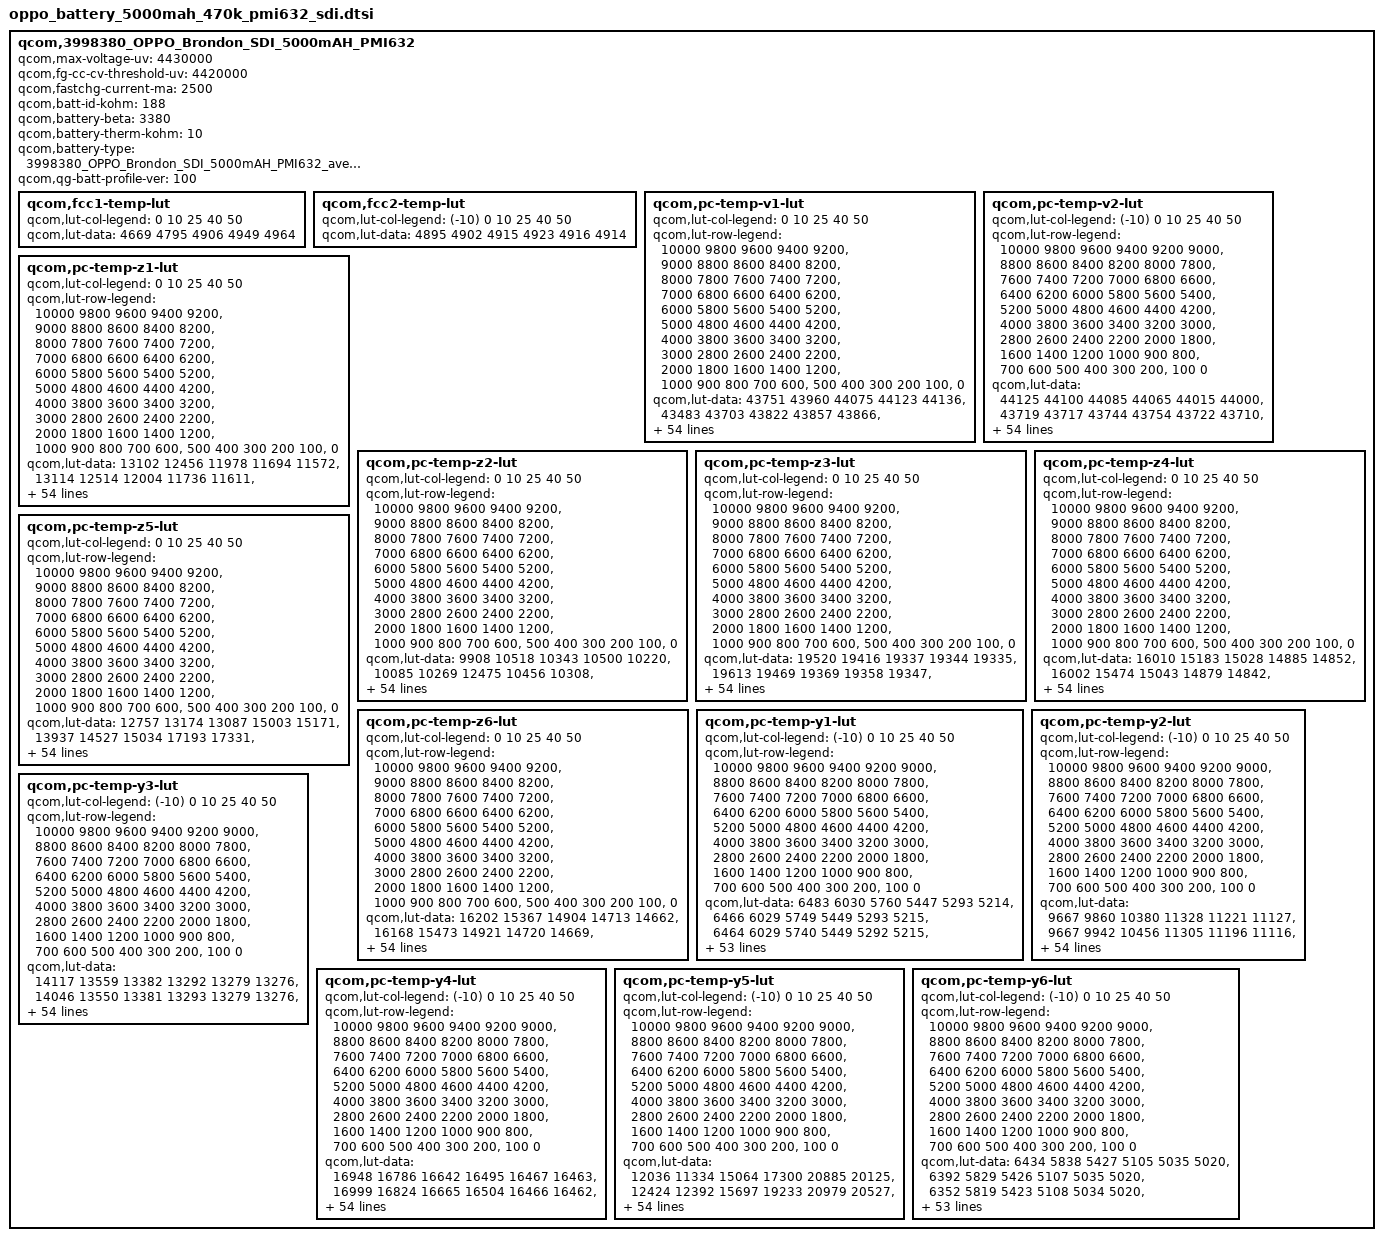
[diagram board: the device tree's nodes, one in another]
qcom,3998380_OPPO_Brondon_SDI_5000mAH_PMI632 {
    /* 3998380_OPPO_Brondon_SDI_5000mAH_PMI632_averaged_MasterSlave_Jun3th2019 */
    qcom,max-voltage-uv = <4430000>;
    qcom,fg-cc-cv-threshold-uv = <4420000>;
    qcom,fastchg-current-ma = <2500>;
    qcom,batt-id-kohm = <188>;
    qcom,battery-beta = <3380>;
    qcom,battery-therm-kohm = <10>;
    qcom,battery-type = "3998380_OPPO_Brondon_SDI_5000mAH_PMI632_averaged_MasterSlave_Jun3th2019";
    qcom,qg-batt-profile-ver = <100>;

	qcom,fcc1-temp-lut {
		qcom,lut-col-legend = <0 10 25 40 50>;
		qcom,lut-data = <4669 4795 4906 4949 4964>;
	};

	qcom,fcc2-temp-lut {
		qcom,lut-col-legend = <(-10) 0 10 25 40 50>;
		qcom,lut-data = <4895 4902 4915 4923 4916 4914>;
	};

	qcom,pc-temp-v1-lut {
		qcom,lut-col-legend = <0 10 25 40 50>;
		qcom,lut-row-legend = <10000 9800 9600 9400 9200>,
			<9000 8800 8600 8400 8200>,
			<8000 7800 7600 7400 7200>,
			<7000 6800 6600 6400 6200>,
			<6000 5800 5600 5400 5200>,
			<5000 4800 4600 4400 4200>,
			<4000 3800 3600 3400 3200>,
			<3000 2800 2600 2400 2200>,
			<2000 1800 1600 1400 1200>,
			<1000 900 800 700 600>,
			<500 400 300 200 100>,
			<0>;
		qcom,lut-data = <43751 43960 44075 44123 44136>,
			<43483 43703 43822 43857 43866>,
			<43224 43456 43576 43603 43610>,
			<42977 43212 43339 43366 43373>,
			<42736 42967 43102 43138 43148>,
			<42498 42723 42857 42904 42918>,
			<42263 42482 42609 42665 42681>,
			<42032 42245 42366 42426 42441>,
			<41807 42012 42128 42189 42204>,
			<41586 41784 41894 41954 41967>,
			<41369 41559 41665 41722 41735>,
			<41158 41340 41442 41491 41508>,
			<40950 41128 41225 41265 41284>,
			<40745 40923 41018 41048 41065>,
			<40537 40720 40815 40836 40850>,
			<40338 40517 40615 40632 40644>,
			<40152 40322 40415 40433 40445>,
			<39976 40143 40227 40244 40254>,
			<39814 39973 40055 40069 40076>,
			<39667 39811 39888 39905 39907>,
			<39532 39662 39711 39728 39729>,
			<39398 39510 39524 39528 39527>,
			<39271 39325 39333 39326 39324>,
			<39146 39101 39113 39128 39132>,
			<39023 38905 38897 38933 38947>,
			<38902 38759 38761 38784 38795>,
			<38785 38638 38671 38677 38678>,
			<38670 38548 38595 38585 38577>,
			<38562 38480 38517 38493 38478>,
			<38476 38423 38445 38404 38384>,
			<38407 38371 38380 38325 38301>,
			<38349 38323 38318 38252 38229>,
			<38300 38280 38262 38187 38164>,
			<38258 38242 38209 38131 38102>,
			<38220 38206 38160 38083 38045>,
			<38185 38170 38112 38032 37986>,
			<38150 38137 38068 37979 37926>,
			<38107 38095 38020 37919 37861>,
			<38051 38031 37952 37843 37778>,
			<37982 37946 37864 37747 37675>,
			<37890 37848 37763 37644 37566>,
			<37767 37733 37646 37540 37460>,
			<37641 37599 37512 37419 37341>,
			<37506 37435 37351 37260 37178>,
			<37351 37283 37204 37118 37040>,
			<37235 37169 37096 37017 36955>,
			<37195 37137 37060 36981 36926>,
			<37160 37111 37033 36957 36899>,
			<37125 37084 37013 36934 36876>,
			<37063 37042 36965 36885 36814>,
			<36867 36856 36751 36642 36545>,
			<36433 36422 36320 36211 36116>,
			<35860 35851 35755 35647 35554>,
			<35084 35070 34985 34880 34786>,
			<33833 33825 33776 33687 33589>,
			<30000 30000 30000 30000 30000>;
	};

	qcom,pc-temp-v2-lut {
		qcom,lut-col-legend = <(-10) 0 10 25 40 50>;
		qcom,lut-row-legend = <10000 9800 9600 9400 9200 9000>,
			<8800 8600 8400 8200 8000 7800>,
			<7600 7400 7200 7000 6800 6600>,
			<6400 6200 6000 5800 5600 5400>,
			<5200 5000 4800 4600 4400 4200>,
			<4000 3800 3600 3400 3200 3000>,
			<2800 2600 2400 2200 2000 1800>,
			<1600 1400 1200 1000 900 800>,
			<700 600 500 400 300 200>,
			<100 0>;
		qcom,lut-data = <44125 44100 44085 44065 44015 44000>,
			<43719 43717 43744 43754 43722 43710>,
			<43347 43369 43428 43464 43446 43438>,
			<43014 43062 43140 43199 43189 43182>,
			<42715 42792 42879 42959 42951 42946>,
			<42438 42535 42626 42724 42717 42713>,
			<42170 42280 42369 42480 42477 42474>,
			<41916 42032 42115 42237 42238 42235>,
			<41670 41783 41870 41998 42001 41998>,
			<41428 41527 41634 41763 41764 41763>,
			<41206 41286 41405 41532 41532 41532>,
			<41027 41082 41180 41305 41305 41305>,
			<40873 40899 40960 41083 41082 41082>,
			<40666 40700 40751 40869 40867 40866>,
			<40323 40478 40554 40661 40660 40655>,
			<39964 40246 40357 40460 40460 40451>,
			<39719 40008 40144 40262 40265 40258>,
			<39527 39761 39922 40068 40077 40073>,
			<39344 39526 39703 39881 39894 39893>,
			<39160 39306 39487 39704 39725 39728>,
			<38984 39101 39278 39524 39552 39557>,
			<38816 38915 39078 39308 39340 39348>,
			<38653 38747 38885 39065 39094 39102>,
			<38514 38592 38714 38860 38885 38892>,
			<38404 38443 38569 38703 38728 38734>,
			<38310 38309 38438 38569 38594 38599>,
			<38227 38213 38314 38449 38475 38479>,
			<38152 38140 38195 38343 38369 38373>,
			<38083 38078 38096 38247 38275 38277>,
			<38018 38019 38021 38159 38188 38187>,
			<37957 37967 37960 38080 38110 38105>,
			<37896 37918 37908 38005 38039 38032>,
			<37837 37871 37865 37934 37975 37970>,
			<37776 37824 37824 37868 37909 37905>,
			<37716 37774 37782 37807 37837 37827>,
			<37654 37720 37739 37750 37759 37739>,
			<37589 37663 37687 37687 37673 37642>,
			<37520 37602 37623 37622 37572 37529>,
			<37448 37535 37549 37551 37473 37421>,
			<37374 37458 37464 37472 37391 37335>,
			<37298 37371 37366 37386 37314 37257>,
			<37223 37275 37261 37288 37223 37167>,
			<37149 37164 37144 37171 37107 37053>,
			<37073 37049 37030 37047 36989 36935>,
			<36991 36931 36922 36919 36874 36815>,
			<36898 36825 36799 36837 36818 36769>,
			<36844 36778 36731 36814 36800 36752>,
			<36777 36734 36671 36789 36782 36735>,
			<36692 36680 36610 36748 36751 36702>,
			<36568 36599 36511 36664 36659 36600>,
			<36365 36422 36322 36413 36378 36288>,
			<36013 36057 35957 35931 35887 35792>,
			<35482 35481 35375 35285 35252 35150>,
			<34660 34644 34561 34388 34380 34268>,
			<33336 33260 33221 33044 33098 32929>,
			<29596 28808 28689 28773 29047 29152>;
	};

	qcom,pc-temp-z1-lut {
		qcom,lut-col-legend = <0 10 25 40 50>;
		qcom,lut-row-legend = <10000 9800 9600 9400 9200>,
			<9000 8800 8600 8400 8200>,
			<8000 7800 7600 7400 7200>,
			<7000 6800 6600 6400 6200>,
			<6000 5800 5600 5400 5200>,
			<5000 4800 4600 4400 4200>,
			<4000 3800 3600 3400 3200>,
			<3000 2800 2600 2400 2200>,
			<2000 1800 1600 1400 1200>,
			<1000 900 800 700 600>,
			<500 400 300 200 100>,
			<0>;
		qcom,lut-data = <13102 12456 11978 11694 11572>,
			<13114 12514 12004 11736 11611>,
			<13120 12508 12015 11757 11633>,
			<13122 12498 12017 11750 11632>,
			<13122 12495 12019 11737 11629>,
			<13117 12492 12012 11729 11625>,
			<13101 12488 11994 11725 11620>,
			<13081 12476 11980 11722 11616>,
			<13059 12459 11968 11716 11613>,
			<13035 12444 11960 11709 11611>,
			<13016 12426 11958 11704 11609>,
			<13004 12412 11957 11700 11606>,
			<12993 12400 11956 11697 11603>,
			<12976 12391 11954 11694 11600>,
			<12946 12386 11952 11691 11598>,
			<12921 12383 11949 11689 11596>,
			<12911 12382 11944 11688 11594>,
			<12904 12382 11942 11687 11593>,
			<12902 12384 11943 11687 11593>,
			<12905 12387 11946 11687 11594>,
			<12907 12394 11949 11687 11594>,
			<12906 12403 11954 11688 11594>,
			<12905 12410 11958 11688 11593>,
			<12908 12416 11957 11689 11594>,
			<12917 12420 11956 11690 11596>,
			<12929 12421 11956 11692 11598>,
			<12936 12421 11962 11696 11601>,
			<12936 12424 11966 11701 11603>,
			<12934 12433 11966 11704 11606>,
			<12935 12441 11966 11706 11609>,
			<12942 12441 11967 11708 11612>,
			<12950 12442 11971 11712 11615>,
			<12960 12443 11977 11717 11619>,
			<12980 12445 11983 11721 11623>,
			<12991 12447 11988 11725 11627>,
			<12987 12451 11993 11729 11632>,
			<12982 12461 11996 11733 11635>,
			<12985 12472 12000 11737 11639>,
			<12996 12482 12007 11743 11644>,
			<13009 12492 12014 11750 11649>,
			<13021 12503 12021 11757 11654>,
			<13032 12514 12026 11763 11658>,
			<13045 12527 12031 11767 11662>,
			<13061 12543 12041 11767 11667>,
			<13103 12537 12046 11776 11671>,
			<13054 12539 12047 11781 11673>,
			<13069 12555 12063 11784 11672>,
			<13071 12565 12048 11783 11673>,
			<13091 12548 12056 11784 11678>,
			<13110 12544 12075 11788 11682>,
			<13080 12548 12076 11799 11691>,
			<13088 12568 12077 11807 11697>,
			<13092 12608 12087 11818 11708>,
			<13135 12642 12114 11835 11721>,
			<13135 12642 12114 11835 11721>,
			<13135 12642 12114 11835 11721>;
	};

	qcom,pc-temp-z2-lut {
		qcom,lut-col-legend = <0 10 25 40 50>;
		qcom,lut-row-legend = <10000 9800 9600 9400 9200>,
			<9000 8800 8600 8400 8200>,
			<8000 7800 7600 7400 7200>,
			<7000 6800 6600 6400 6200>,
			<6000 5800 5600 5400 5200>,
			<5000 4800 4600 4400 4200>,
			<4000 3800 3600 3400 3200>,
			<3000 2800 2600 2400 2200>,
			<2000 1800 1600 1400 1200>,
			<1000 900 800 700 600>,
			<500 400 300 200 100>,
			<0>;
		qcom,lut-data = <9908 10518 10343 10500 10220>,
			<10085 10269 12475 10456 10308>,
			<10186 10382 12866 10438 10355>,
			<10236 10446 12356 10450 10352>,
			<10266 10437 11736 10470 10340>,
			<10275 10407 11201 10473 10337>,
			<10276 10381 10701 10464 10340>,
			<10275 10365 10536 10450 10339>,
			<10271 10350 10491 10403 10309>,
			<10261 10337 10464 10329 10246>,
			<10251 10325 10592 10298 10213>,
			<10243 10318 10927 10290 10201>,
			<10235 10316 11109 10291 10194>,
			<10224 10314 11402 10309 10203>,
			<10202 10316 11763 10336 10230>,
			<10185 10332 11896 10344 10247>,
			<10184 10354 11977 10323 10254>,
			<10184 10371 12000 10305 10259>,
			<10184 10388 11417 10309 10273>,
			<10191 10408 10634 10315 10295>,
			<10203 10432 10513 10329 10314>,
			<10210 10458 10557 10378 10337>,
			<10216 10482 10588 10420 10359>,
			<10221 10508 10592 10416 10373>,
			<10235 10522 10594 10396 10386>,
			<10260 10522 10595 10380 10395>,
			<10280 10522 10589 10384 10468>,
			<10291 10523 10583 10399 10553>,
			<10301 10533 10578 10440 10560>,
			<10312 10543 10574 10523 10536>,
			<10326 10547 10573 10557 10490>,
			<10339 10552 10584 10521 10370>,
			<10347 10554 10596 10464 10251>,
			<10354 10554 10605 10409 10237>,
			<10361 10554 10612 10349 10238>,
			<10371 10557 10617 10325 10241>,
			<10385 10573 10618 10341 10266>,
			<10403 10593 10619 10373 10310>,
			<10434 10613 10628 10428 10355>,
			<10463 10633 10651 10537 10412>,
			<10477 10640 10670 10591 10438>,
			<10488 10636 10686 10530 10420>,
			<10339 10635 10695 10477 10403>,
			<9937 10651 10686 10476 10408>,
			<10052 10786 10703 10500 10410>,
			<10076 10822 10667 10549 10400>,
			<10142 10805 10630 10489 10415>,
			<10181 10785 10653 10522 10427>,
			<10271 10793 10654 10524 10457>,
			<10340 11036 10689 10643 10530>,
			<10128 11444 10710 10492 10397>,
			<9900 10452 10664 10407 10264>,
			<9755 10492 10567 10379 10224>,
			<9628 10151 10476 10309 10175>,
			<9628 10151 10476 10309 10175>,
			<9628 10151 10476 10309 10175>;
	};

	qcom,pc-temp-z3-lut {
		qcom,lut-col-legend = <0 10 25 40 50>;
		qcom,lut-row-legend = <10000 9800 9600 9400 9200>,
			<9000 8800 8600 8400 8200>,
			<8000 7800 7600 7400 7200>,
			<7000 6800 6600 6400 6200>,
			<6000 5800 5600 5400 5200>,
			<5000 4800 4600 4400 4200>,
			<4000 3800 3600 3400 3200>,
			<3000 2800 2600 2400 2200>,
			<2000 1800 1600 1400 1200>,
			<1000 900 800 700 600>,
			<500 400 300 200 100>,
			<0>;
		qcom,lut-data = <19520 19416 19337 19344 19335>,
			<19613 19469 19369 19358 19347>,
			<19654 19505 19385 19368 19356>,
			<19661 19531 19404 19374 19361>,
			<19664 19541 19421 19378 19364>,
			<19664 19547 19427 19381 19368>,
			<19655 19549 19431 19384 19373>,
			<19644 19545 19432 19385 19376>,
			<19635 19540 19431 19384 19376>,
			<19625 19534 19430 19382 19376>,
			<19620 19528 19430 19381 19374>,
			<19619 19521 19433 19378 19370>,
			<19618 19515 19434 19376 19366>,
			<19616 19509 19435 19374 19363>,
			<19614 19503 19436 19372 19361>,
			<19611 19496 19434 19369 19360>,
			<19604 19490 19430 19366 19357>,
			<19594 19483 19425 19363 19355>,
			<19582 19474 19410 19359 19352>,
			<19565 19470 19395 19356 19348>,
			<19548 19467 19393 19354 19347>,
			<19542 19465 19397 19357 19349>,
			<19546 19468 19400 19360 19351>,
			<19551 19480 19399 19358 19348>,
			<19559 19488 19398 19352 19340>,
			<19575 19488 19398 19350 19336>,
			<19586 19486 19396 19351 19349>,
			<19591 19485 19395 19354 19366>,
			<19594 19483 19396 19361 19373>,
			<19594 19480 19399 19374 19379>,
			<19587 19478 19401 19379 19381>,
			<19578 19475 19402 19379 19376>,
			<19570 19472 19403 19379 19368>,
			<19562 19469 19403 19376 19362>,
			<19553 19466 19402 19370 19358>,
			<19543 19463 19401 19364 19353>,
			<19532 19459 19397 19358 19347>,
			<19523 19456 19392 19354 19342>,
			<19513 19454 19391 19354 19342>,
			<19506 19452 19389 19355 19342>,
			<19504 19449 19388 19355 19343>,
			<19503 19443 19384 19350 19342>,
			<19438 19440 19382 19347 19342>,
			<19267 19439 19380 19348 19346>,
			<19263 19419 19373 19345 19345>,
			<19263 19410 19366 19340 19338>,
			<19263 19379 19362 19339 19329>,
			<19262 19330 19364 19333 19324>,
			<19262 19299 19351 19330 19320>,
			<19261 19263 19349 19318 19313>,
			<19262 19260 19346 19337 19335>,
			<19265 19266 19346 19345 19344>,
			<19266 19264 19349 19345 19340>,
			<19269 19269 19355 19346 19341>,
			<19269 19269 19355 19346 19341>,
			<19269 19269 19355 19346 19341>;
	};

	qcom,pc-temp-z4-lut {
		qcom,lut-col-legend = <0 10 25 40 50>;
		qcom,lut-row-legend = <10000 9800 9600 9400 9200>,
			<9000 8800 8600 8400 8200>,
			<8000 7800 7600 7400 7200>,
			<7000 6800 6600 6400 6200>,
			<6000 5800 5600 5400 5200>,
			<5000 4800 4600 4400 4200>,
			<4000 3800 3600 3400 3200>,
			<3000 2800 2600 2400 2200>,
			<2000 1800 1600 1400 1200>,
			<1000 900 800 700 600>,
			<500 400 300 200 100>,
			<0>;
		qcom,lut-data = <16010 15183 15028 14885 14852>,
			<16002 15474 15043 14879 14842>,
			<15978 15367 15036 14868 14830>,
			<15824 15231 14964 14845 14814>,
			<15594 15126 14882 14813 14794>,
			<15437 15025 14840 14787 14776>,
			<15321 14949 14809 14766 14759>,
			<15224 14891 14782 14748 14743>,
			<15146 14845 14759 14732 14728>,
			<15080 14810 14737 14718 14714>,
			<15023 14782 14713 14708 14706>,
			<14973 14758 14686 14700 14703>,
			<14929 14738 14669 14695 14700>,
			<14896 14720 14653 14689 14696>,
			<14869 14711 14639 14684 14691>,
			<14848 14705 14637 14680 14687>,
			<14830 14700 14636 14678 14683>,
			<14815 14695 14636 14675 14679>,
			<14806 14691 14644 14670 14674>,
			<14803 14686 14659 14663 14667>,
			<14800 14679 14670 14661 14665>,
			<14794 14674 14680 14677 14681>,
			<14781 14682 14693 14701 14707>,
			<14765 14720 14734 14732 14734>,
			<14750 14753 14784 14770 14767>,
			<14729 14766 14794 14783 14780>,
			<14719 14775 14782 14773 14759>,
			<14722 14776 14767 14755 14728>,
			<14726 14765 14754 14736 14710>,
			<14726 14750 14741 14714 14696>,
			<14725 14738 14729 14700 14687>,
			<14723 14727 14718 14692 14683>,
			<14720 14717 14708 14686 14679>,
			<14715 14708 14700 14680 14674>,
			<14710 14699 14694 14675 14668>,
			<14706 14690 14689 14672 14665>,
			<14703 14681 14684 14671 14665>,
			<14699 14677 14681 14670 14665>,
			<14696 14676 14681 14672 14668>,
			<14692 14676 14681 14677 14678>,
			<14689 14675 14681 14680 14684>,
			<14685 14673 14678 14676 14675>,
			<14751 14671 14673 14671 14667>,
			<14928 14667 14669 14668 14667>,
			<14876 14656 14656 14657 14659>,
			<14871 14653 14651 14649 14648>,
			<14866 14679 14648 14645 14646>,
			<14862 14728 14639 14638 14640>,
			<14857 14757 14640 14627 14626>,
			<14854 14788 14635 14629 14621>,
			<14857 14793 14649 14632 14636>,
			<14879 14808 14662 14640 14645>,
			<14895 14817 14663 14644 14652>,
			<14913 14827 14661 14648 14655>,
			<14913 14827 14661 14648 14655>,
			<14913 14827 14661 14648 14655>;
	};

	qcom,pc-temp-z5-lut {
		qcom,lut-col-legend = <0 10 25 40 50>;
		qcom,lut-row-legend = <10000 9800 9600 9400 9200>,
			<9000 8800 8600 8400 8200>,
			<8000 7800 7600 7400 7200>,
			<7000 6800 6600 6400 6200>,
			<6000 5800 5600 5400 5200>,
			<5000 4800 4600 4400 4200>,
			<4000 3800 3600 3400 3200>,
			<3000 2800 2600 2400 2200>,
			<2000 1800 1600 1400 1200>,
			<1000 900 800 700 600>,
			<500 400 300 200 100>,
			<0>;
		qcom,lut-data = <12757 13174 13087 15003 15171>,
			<13937 14527 15034 17193 17331>,
			<14815 15610 16425 18786 18953>,
			<15417 16729 17558 19707 19880>,
			<15907 17762 18728 20390 20528>,
			<16387 18725 20120 21170 21372>,
			<16851 19602 21636 22142 22600>,
			<17268 20410 22906 22930 23924>,
			<17608 21174 23834 23390 25307>,
			<17910 21905 24915 23881 26699>,
			<18284 22609 27396 24531 27107>,
			<18904 23416 31589 25534 26823>,
			<19665 24623 35065 26592 26546>,
			<20422 25968 39311 27616 26893>,
			<21283 26946 43114 28691 28079>,
			<21933 28076 44023 29374 29234>,
			<22150 28889 44352 29758 30168>,
			<22134 28875 44355 30125 31204>,
			<21905 28587 39979 30803 32763>,
			<20838 28607 34191 31964 34820>,
			<19499 30377 34908 33505 36168>,
			<19275 33892 42533 36402 37139>,
			<20197 40978 47350 38667 37805>,
			<21632 56282 44463 35751 34826>,
			<24430 65485 38877 27393 25191>,
			<30326 62471 34639 22974 20678>,
			<36425 56294 30787 21661 21800>,
			<43098 51806 28731 20974 23752>,
			<49026 48380 28951 22096 26550>,
			<50193 45931 29655 26108 31461>,
			<48714 44776 30682 29948 33763>,
			<46543 43993 32776 33558 33700>,
			<44133 43571 35468 36329 33591>,
			<41040 43487 38980 37060 34044>,
			<38285 43557 43041 37415 35577>,
			<35337 43634 44337 37562 36380>,
			<32237 43846 44077 37450 35741>,
			<30396 44103 43665 37365 34899>,
			<29059 45123 43152 37899 34907>,
			<28257 46804 42094 39255 35450>,
			<28935 46756 40645 39871 35743>,
			<30838 41165 37578 33653 33042>,
			<25834 38607 35335 28654 30695>,
			<11634 40326 34849 30327 35680>,
			<11744 37891 34077 30263 36866>,
			<11739 35109 30462 27926 29902>,
			<11690 24214 28956 26723 23383>,
			<11638 19092 31555 25259 22517>,
			<11628 13253 24542 27291 24244>,
			<11632 11757 24820 21560 24032>,
			<11661 11733 21301 29828 34762>,
			<11700 11804 18897 26409 27413>,
			<11568 11671 18705 23871 22106>,
			<11469 11609 19375 21524 19357>,
			<11469 11609 19375 21524 19357>,
			<11469 11609 19375 21524 19357>;
	};

	qcom,pc-temp-z6-lut {
		qcom,lut-col-legend = <0 10 25 40 50>;
		qcom,lut-row-legend = <10000 9800 9600 9400 9200>,
			<9000 8800 8600 8400 8200>,
			<8000 7800 7600 7400 7200>,
			<7000 6800 6600 6400 6200>,
			<6000 5800 5600 5400 5200>,
			<5000 4800 4600 4400 4200>,
			<4000 3800 3600 3400 3200>,
			<3000 2800 2600 2400 2200>,
			<2000 1800 1600 1400 1200>,
			<1000 900 800 700 600>,
			<500 400 300 200 100>,
			<0>;
		qcom,lut-data = <16202 15367 14904 14713 14662>,
			<16168 15473 14921 14720 14669>,
			<16106 15405 14919 14722 14671>,
			<15985 15318 14888 14715 14667>,
			<15835 15249 14849 14700 14659>,
			<15721 15181 14825 14688 14653>,
			<15629 15124 14804 14678 14647>,
			<15550 15076 14786 14669 14642>,
			<15484 15036 14768 14660 14636>,
			<15427 15003 14753 14651 14629>,
			<15380 14975 14739 14645 14624>,
			<15339 14951 14728 14639 14619>,
			<15304 14929 14719 14635 14615>,
			<15272 14910 14712 14630 14611>,
			<15244 14898 14706 14626 14608>,
			<15219 14890 14702 14623 14604>,
			<15196 14884 14699 14620 14601>,
			<15175 14877 14696 14616 14597>,
			<15159 14871 14692 14612 14593>,
			<15146 14868 14689 14606 14588>,
			<15136 14865 14689 14605 14587>,
			<15133 14864 14696 14613 14594>,
			<15133 14870 14705 14625 14606>,
			<15133 14894 14724 14638 14617>,
			<15134 14914 14746 14652 14627>,
			<15137 14921 14750 14657 14632>,
			<15142 14925 14745 14653 14629>,
			<15148 14926 14739 14648 14626>,
			<15155 14921 14735 14645 14623>,
			<15157 14915 14732 14643 14621>,
			<15155 14911 14729 14640 14618>,
			<15152 14907 14726 14638 14614>,
			<15150 14903 14724 14635 14609>,
			<15147 14900 14722 14632 14605>,
			<15144 14897 14720 14627 14601>,
			<15142 14895 14719 14623 14597>,
			<15141 14893 14717 14621 14594>,
			<15141 14892 14715 14619 14592>,
			<15142 14895 14716 14620 14593>,
			<15144 14900 14719 14625 14598>,
			<15149 14903 14720 14627 14601>,
			<15156 14905 14720 14624 14598>,
			<15161 14907 14720 14621 14595>,
			<15164 14913 14721 14621 14598>,
			<15159 14910 14716 14617 14595>,
			<15155 14907 14713 14611 14587>,
			<15153 14905 14711 14610 14582>,
			<15153 14900 14708 14604 14576>,
			<15154 14899 14703 14598 14569>,
			<15156 14900 14703 14594 14564>,
			<15166 14907 14712 14607 14583>,
			<15185 14923 14721 14618 14594>,
			<15206 14935 14728 14622 14598>,
			<15234 14957 14738 14628 14603>,
			<15234 14957 14738 14628 14603>,
			<15234 14957 14738 14628 14603>;
	};

	qcom,pc-temp-y1-lut {
		qcom,lut-col-legend = <(-10) 0 10 25 40 50>;
		qcom,lut-row-legend = <10000 9800 9600 9400 9200 9000>,
			<8800 8600 8400 8200 8000 7800>,
			<7600 7400 7200 7000 6800 6600>,
			<6400 6200 6000 5800 5600 5400>,
			<5200 5000 4800 4600 4400 4200>,
			<4000 3800 3600 3400 3200 3000>,
			<2800 2600 2400 2200 2000 1800>,
			<1600 1400 1200 1000 900 800>,
			<700 600 500 400 300 200>,
			<100 0>;
		qcom,lut-data = <6483 6030 5760 5447 5293 5214>,
			<6466 6029 5749 5449 5293 5215>,
			<6464 6029 5740 5449 5292 5215>,
			<6471 6029 5733 5448 5291 5214>,
			<6480 6029 5729 5447 5288 5213>,
			<6485 6030 5726 5446 5286 5210>,
			<6494 6039 5726 5443 5282 5207>,
			<6512 6058 5727 5440 5278 5203>,
			<6517 6063 5729 5438 5274 5200>,
			<6510 6050 5730 5436 5269 5197>,
			<6503 6039 5731 5434 5265 5195>,
			<6503 6037 5733 5432 5263 5193>,
			<6508 6036 5738 5428 5260 5192>,
			<6512 6036 5739 5427 5258 5190>,
			<6525 6042 5732 5427 5255 5187>,
			<6539 6049 5726 5427 5253 5185>,
			<6539 6055 5725 5425 5251 5185>,
			<6534 6060 5724 5422 5250 5187>,
			<6528 6062 5724 5421 5249 5188>,
			<6511 6056 5727 5425 5248 5184>,
			<6491 6049 5729 5430 5248 5181>,
			<6483 6053 5729 5430 5248 5180>,
			<6475 6069 5729 5429 5249 5181>,
			<6472 6080 5729 5428 5250 5181>,
			<6480 6082 5729 5430 5250 5182>,
			<6493 6081 5728 5432 5250 5183>,
			<6498 6080 5731 5432 5251 5184>,
			<6509 6071 5743 5432 5254 5186>,
			<6516 6065 5751 5432 5257 5188>,
			<6507 6059 5744 5435 5259 5191>,
			<6489 6051 5734 5438 5262 5193>,
			<6481 6048 5731 5441 5264 5195>,
			<6479 6046 5731 5444 5267 5195>,
			<6479 6045 5731 5446 5269 5195>,
			<6483 6050 5732 5447 5273 5197>,
			<6488 6061 5733 5447 5276 5200>,
			<6489 6064 5734 5448 5277 5202>,
			<6479 6064 5740 5452 5277 5205>,
			<6468 6063 5744 5455 5277 5207>,
			<6468 6059 5750 5455 5279 5208>,
			<6474 6051 5760 5455 5282 5208>,
			<6477 6044 5761 5456 5284 5210>,
			<6468 6036 5749 5458 5285 5213>,
			<6460 6035 5741 5463 5288 5216>,
			<6442 6048 5739 5471 5295 5218>,
			<6445 6062 5745 5485 5300 5223>,
			<6454 6072 5751 5488 5302 5225>,
			<6470 6074 5756 5486 5304 5225>,
			<6480 6067 5752 5485 5304 5224>,
			<6527 6086 5756 5492 5302 5222>,
			<6464 6063 5757 5495 5304 5222>,
			<6537 6101 5759 5505 5313 5235>,
			<6569 6092 5780 5521 5321 5241>,
			<6666 6115 5788 5529 5336 5249>,
			<6666 6115 5788 5529 5336 5249>,
			<6666 6115 5788 5529 5336 5249>;
	};

	qcom,pc-temp-y2-lut {
		qcom,lut-col-legend = <(-10) 0 10 25 40 50>;
		qcom,lut-row-legend = <10000 9800 9600 9400 9200 9000>,
			<8800 8600 8400 8200 8000 7800>,
			<7600 7400 7200 7000 6800 6600>,
			<6400 6200 6000 5800 5600 5400>,
			<5200 5000 4800 4600 4400 4200>,
			<4000 3800 3600 3400 3200 3000>,
			<2800 2600 2400 2200 2000 1800>,
			<1600 1400 1200 1000 900 800>,
			<700 600 500 400 300 200>,
			<100 0>;
		qcom,lut-data = <9667 9860 10380 11328 11221 11127>,
			<9667 9942 10456 11305 11196 11116>,
			<9668 10029 10537 11282 11166 11094>,
			<9670 10113 10615 11258 11134 11067>,
			<9671 10185 10681 11234 11106 11043>,
			<9672 10235 10727 11210 11085 11029>,
			<9672 10260 10755 11185 11073 11012>,
			<9673 10277 10775 11160 11061 10981>,
			<9673 10320 10785 11136 11046 10958>,
			<9672 10461 10789 11109 11026 10937>,
			<9672 10582 10794 11092 11007 10921>,
			<9673 10601 10832 11099 10991 10912>,
			<9674 10609 10915 11115 10975 10907>,
			<9675 10626 10980 11123 10964 10907>,
			<9673 10696 11030 11136 10956 10908>,
			<9671 10771 11070 11156 10950 10909>,
			<9671 10804 11100 11189 10981 10909>,
			<9671 10826 11127 11247 11076 10906>,
			<9671 10821 11135 11308 11149 10917>,
			<9671 10387 11132 11388 11217 11042>,
			<9671 9853 11128 11447 11268 11177>,
			<9671 9758 11130 11428 11255 11185>,
			<9671 9742 11138 11356 11201 11162>,
			<9670 9729 11142 11320 11169 11142>,
			<9670 9715 11139 11322 11157 11118>,
			<9670 9704 11132 11330 11149 11095>,
			<9669 9698 11117 11340 11158 11095>,
			<9669 9694 11082 11355 11183 11113>,
			<9668 9691 11047 11366 11220 11140>,
			<9668 9689 11022 11384 11303 11190>,
			<9668 9687 10998 11406 11398 11251>,
			<9667 9685 10969 11410 11412 11268>,
			<9667 9683 10936 11403 11370 11261>,
			<9666 9680 10896 11398 11338 11254>,
			<9666 9677 10850 11409 11341 11268>,
			<9666 9675 10786 11426 11345 11288>,
			<9665 9673 10651 11417 11342 11286>,
			<9665 9671 10277 11369 11316 11224>,
			<9664 9669 9948 11310 11298 11162>,
			<9664 9667 9835 11254 11301 11138>,
			<9664 9666 9763 11193 11304 11118>,
			<9663 9665 9723 11137 11302 11114>,
			<9663 9664 9699 11082 11267 11112>,
			<9662 9663 9687 10993 11222 11092>,
			<9662 9662 9680 10843 11170 11034>,
			<9661 9661 9673 10739 11058 10937>,
			<9660 9660 9671 10782 11048 10917>,
			<9660 9660 9670 10812 11085 10924>,
			<9659 9659 9668 10820 11155 10920>,
			<9658 9659 9667 10822 11103 10891>,
			<9657 9658 9664 10713 11028 10876>,
			<9654 9657 9662 10542 10969 10848>,
			<9651 9655 9659 10401 10865 10725>,
			<9650 9652 9657 10301 10791 10585>,
			<9650 9652 9657 10301 10791 10585>,
			<9650 9652 9657 10301 10791 10585>;
	};

	qcom,pc-temp-y3-lut {
		qcom,lut-col-legend = <(-10) 0 10 25 40 50>;
		qcom,lut-row-legend = <10000 9800 9600 9400 9200 9000>,
			<8800 8600 8400 8200 8000 7800>,
			<7600 7400 7200 7000 6800 6600>,
			<6400 6200 6000 5800 5600 5400>,
			<5200 5000 4800 4600 4400 4200>,
			<4000 3800 3600 3400 3200 3000>,
			<2800 2600 2400 2200 2000 1800>,
			<1600 1400 1200 1000 900 800>,
			<700 600 500 400 300 200>,
			<100 0>;
		qcom,lut-data = <14117 13559 13382 13292 13279 13276>,
			<14046 13550 13381 13293 13279 13276>,
			<13978 13541 13380 13295 13280 13277>,
			<13915 13532 13380 13297 13280 13277>,
			<13858 13524 13379 13298 13281 13278>,
			<13810 13517 13377 13299 13281 13278>,
			<13772 13512 13376 13299 13282 13279>,
			<13739 13506 13374 13300 13283 13280>,
			<13703 13498 13373 13300 13283 13280>,
			<13656 13486 13374 13300 13283 13281>,
			<13624 13470 13375 13301 13283 13281>,
			<13619 13450 13373 13301 13284 13282>,
			<13617 13427 13367 13302 13284 13282>,
			<13612 13419 13361 13302 13284 13282>,
			<13582 13419 13356 13302 13286 13283>,
			<13547 13420 13351 13302 13288 13283>,
			<13533 13413 13347 13302 13289 13283>,
			<13524 13393 13344 13300 13289 13285>,
			<13520 13383 13341 13300 13290 13286>,
			<13518 13382 13336 13300 13289 13286>,
			<13518 13382 13331 13299 13288 13287>,
			<13517 13383 13326 13298 13286 13285>,
			<13512 13385 13322 13294 13283 13281>,
			<13509 13386 13319 13291 13281 13278>,
			<13512 13378 13316 13290 13280 13277>,
			<13519 13367 13313 13290 13280 13276>,
			<13528 13365 13312 13289 13279 13276>,
			<13541 13368 13311 13288 13279 13277>,
			<13556 13372 13311 13288 13278 13277>,
			<13569 13381 13310 13288 13279 13277>,
			<13583 13395 13309 13288 13279 13275>,
			<13600 13409 13310 13288 13279 13275>,
			<13620 13425 13312 13288 13279 13276>,
			<13642 13442 13316 13287 13279 13277>,
			<13665 13459 13319 13288 13279 13277>,
			<13688 13476 13322 13288 13279 13277>,
			<13714 13497 13327 13288 13279 13277>,
			<13742 13526 13332 13288 13278 13277>,
			<13771 13558 13339 13288 13277 13276>,
			<13800 13591 13350 13289 13278 13277>,
			<13829 13626 13365 13289 13279 13278>,
			<13863 13664 13385 13290 13280 13279>,
			<13903 13708 13411 13292 13279 13279>,
			<13952 13753 13447 13295 13279 13278>,
			<14012 13800 13498 13297 13280 13276>,
			<14102 13863 13560 13302 13284 13282>,
			<14133 13882 13561 13304 13285 13284>,
			<14139 13896 13569 13307 13287 13285>,
			<14233 13959 13614 13312 13289 13286>,
			<14367 14026 13655 13318 13289 13285>,
			<14568 14117 13706 13318 13286 13282>,
			<15018 14270 13777 13321 13286 13282>,
			<16549 14609 13914 13335 13290 13286>,
			<20201 15695 14165 13364 13298 13293>,
			<20201 15695 14165 13364 13298 13293>,
			<20201 15695 14165 13364 13298 13293>;
	};

	qcom,pc-temp-y4-lut {
		qcom,lut-col-legend = <(-10) 0 10 25 40 50>;
		qcom,lut-row-legend = <10000 9800 9600 9400 9200 9000>,
			<8800 8600 8400 8200 8000 7800>,
			<7600 7400 7200 7000 6800 6600>,
			<6400 6200 6000 5800 5600 5400>,
			<5200 5000 4800 4600 4400 4200>,
			<4000 3800 3600 3400 3200 3000>,
			<2800 2600 2400 2200 2000 1800>,
			<1600 1400 1200 1000 900 800>,
			<700 600 500 400 300 200>,
			<100 0>;
		qcom,lut-data = <16948 16786 16642 16495 16467 16463>,
			<16999 16824 16665 16504 16466 16462>,
			<17049 16872 16698 16511 16465 16461>,
			<17093 16920 16733 16516 16464 16460>,
			<17124 16957 16761 16519 16463 16459>,
			<17138 16974 16773 16520 16462 16458>,
			<17129 16970 16771 16518 16462 16458>,
			<17112 16960 16766 16514 16461 16457>,
			<17109 16954 16762 16513 16461 16457>,
			<17136 16947 16757 16514 16463 16458>,
			<17160 16942 16755 16515 16466 16459>,
			<17160 16971 16762 16517 16469 16461>,
			<17152 17041 16783 16522 16472 16463>,
			<17136 17064 16802 16529 16476 16466>,
			<17028 17013 16825 16541 16481 16469>,
			<16905 16942 16840 16556 16487 16474>,
			<16862 16887 16829 16574 16494 16479>,
			<16840 16834 16789 16594 16504 16486>,
			<16816 16793 16750 16608 16517 16495>,
			<16783 16765 16717 16618 16545 16519>,
			<16749 16741 16683 16625 16570 16541>,
			<16719 16706 16646 16604 16557 16533>,
			<16690 16663 16608 16536 16506 16496>,
			<16676 16631 16580 16494 16472 16470>,
			<16676 16612 16565 16480 16461 16461>,
			<16677 16599 16553 16472 16454 16455>,
			<16678 16598 16534 16472 16454 16454>,
			<16679 16604 16509 16473 16456 16455>,
			<16681 16611 16496 16475 16459 16455>,
			<16684 16616 16498 16479 16464 16459>,
			<16689 16622 16502 16483 16470 16467>,
			<16693 16629 16508 16485 16478 16475>,
			<16698 16636 16518 16486 16489 16486>,
			<16703 16645 16530 16486 16495 16493>,
			<16707 16657 16544 16486 16493 16493>,
			<16711 16670 16559 16484 16490 16491>,
			<16715 16682 16575 16483 16483 16487>,
			<16720 16694 16592 16481 16466 16470>,
			<16727 16705 16609 16480 16454 16457>,
			<16735 16716 16624 16482 16457 16461>,
			<16747 16726 16637 16488 16463 16469>,
			<16760 16732 16653 16493 16465 16472>,
			<16778 16735 16670 16498 16463 16469>,
			<16800 16737 16695 16503 16460 16463>,
			<16827 16738 16733 16510 16452 16446>,
			<16842 16740 16797 16536 16469 16470>,
			<16841 16734 16788 16538 16486 16494>,
			<16776 16705 16781 16551 16509 16523>,
			<16795 16729 16840 16588 16540 16552>,
			<16819 16767 16894 16627 16547 16548>,
			<16819 16773 16922 16606 16502 16487>,
			<16820 16752 16918 16585 16479 16471>,
			<17126 16746 16905 16607 16488 16473>,
			<18307 17007 16930 16652 16514 16489>,
			<18307 17007 16930 16652 16514 16489>,
			<18307 17007 16930 16652 16514 16489>;
	};

	qcom,pc-temp-y5-lut {
		qcom,lut-col-legend = <(-10) 0 10 25 40 50>;
		qcom,lut-row-legend = <10000 9800 9600 9400 9200 9000>,
			<8800 8600 8400 8200 8000 7800>,
			<7600 7400 7200 7000 6800 6600>,
			<6400 6200 6000 5800 5600 5400>,
			<5200 5000 4800 4600 4400 4200>,
			<4000 3800 3600 3400 3200 3000>,
			<2800 2600 2400 2200 2000 1800>,
			<1600 1400 1200 1000 900 800>,
			<700 600 500 400 300 200>,
			<100 0>;
		qcom,lut-data = <12036 11334 15064 17300 20885 20125>,
			<12424 12392 15697 19233 20979 20527>,
			<12837 13405 16344 20557 20926 20813>,
			<13235 14350 16954 21379 20788 21000>,
			<13578 15202 17478 21801 20624 21102>,
			<13828 15938 17865 21927 20492 21136>,
			<14006 16654 18095 21600 20390 21083>,
			<14143 17264 18271 20867 20234 20943>,
			<14151 17366 18551 20265 19922 20759>,
			<13913 16946 19108 19760 18998 20383>,
			<13698 16575 19500 19275 18036 19901>,
			<15110 16699 18957 18813 17436 19345>,
			<18596 17173 17722 18359 16933 18650>,
			<19828 17968 17364 17816 16756 17992>,
			<17635 20678 18316 16954 16965 17234>,
			<15274 23193 19590 16327 17175 16696>,
			<15076 23048 20455 16355 17017 16612>,
			<15257 21845 21206 16599 16688 16584>,
			<15354 20699 21882 17094 16573 16598>,
			<15623 19557 22640 19534 17010 16820>,
			<15942 18678 23244 22476 17858 17267>,
			<15667 18726 23400 24069 19490 18419>,
			<14486 19283 23377 25283 22428 20871>,
			<13592 19584 23380 25691 23773 22086>,
			<13300 17474 23636 25265 23560 21690>,
			<13112 14374 23942 24525 23116 21093>,
			<13060 13606 23898 23751 22396 20934>,
			<13144 13455 23394 22800 21038 20678>,
			<13256 13399 22673 22365 20123 20290>,
			<13360 13463 21210 22769 20033 19053>,
			<13496 13620 19537 23366 20165 17508>,
			<13618 13828 19168 23557 20261 17303>,
			<13728 14196 19467 23873 20537 18021>,
			<13836 14445 19727 24097 20959 18981>,
			<13967 14417 19828 24286 22361 20481>,
			<14100 14344 19926 24536 24345 22243>,
			<14137 14318 19657 24516 24678 22825>,
			<14058 14407 18372 23900 23581 22920>,
			<13931 14486 17024 23104 22571 22920>,
			<13778 14446 16253 21821 22572 23168>,
			<13583 14342 15621 20279 23070 23779>,
			<13481 14274 15025 19940 23242 24139>,
			<13498 14131 14401 20126 22539 24983>,
			<13562 13958 14142 20019 21893 24420>,
			<13703 13774 14097 18659 21070 18999>,
			<13977 13729 13705 17663 20044 18526>,
			<14185 13753 13822 18164 19188 17733>,
			<14403 14136 14730 18400 18377 16686>,
			<14506 14273 15482 18268 17944 16238>,
			<14500 14419 16046 18585 17625 15930>,
			<14824 14620 16195 18329 18630 16671>,
			<13985 14239 15448 17923 19784 17331>,
			<11783 13815 13925 17165 20051 17951>,
			<10004 11934 12980 16797 23017 22040>,
			<10004 11934 12980 16797 23017 22040>,
			<10004 11934 12980 16797 23017 22040>;
	};

	qcom,pc-temp-y6-lut {
		qcom,lut-col-legend = <(-10) 0 10 25 40 50>;
		qcom,lut-row-legend = <10000 9800 9600 9400 9200 9000>,
			<8800 8600 8400 8200 8000 7800>,
			<7600 7400 7200 7000 6800 6600>,
			<6400 6200 6000 5800 5600 5400>,
			<5200 5000 4800 4600 4400 4200>,
			<4000 3800 3600 3400 3200 3000>,
			<2800 2600 2400 2200 2000 1800>,
			<1600 1400 1200 1000 900 800>,
			<700 600 500 400 300 200>,
			<100 0>;
		qcom,lut-data = <6434 5838 5427 5105 5035 5020>,
			<6392 5829 5426 5107 5035 5020>,
			<6352 5819 5423 5108 5034 5020>,
			<6313 5808 5418 5108 5034 5020>,
			<6275 5797 5412 5108 5034 5020>,
			<6239 5784 5405 5107 5033 5020>,
			<6204 5771 5396 5105 5033 5020>,
			<6170 5757 5385 5102 5033 5020>,
			<6141 5741 5377 5099 5033 5020>,
			<6113 5720 5369 5098 5033 5021>,
			<6092 5705 5363 5097 5033 5021>,
			<6082 5700 5358 5097 5033 5022>,
			<6077 5698 5354 5098 5034 5022>,
			<6065 5693 5352 5098 5035 5023>,
			<6015 5680 5351 5101 5037 5024>,
			<5959 5663 5350 5104 5040 5025>,
			<5938 5642 5344 5108 5043 5027>,
			<5926 5617 5330 5113 5046 5030>,
			<5916 5596 5315 5116 5050 5034>,
			<5907 5580 5302 5118 5057 5040>,
			<5899 5566 5288 5119 5063 5046>,
			<5889 5555 5274 5112 5058 5043>,
			<5878 5546 5261 5090 5041 5029>,
			<5872 5539 5252 5076 5029 5019>,
			<5877 5534 5249 5072 5026 5016>,
			<5886 5531 5246 5069 5023 5013>,
			<5894 5533 5243 5069 5023 5013>,
			<5903 5544 5241 5070 5024 5014>,
			<5914 5560 5240 5071 5025 5015>,
			<5926 5575 5244 5073 5026 5016>,
			<5939 5593 5252 5075 5029 5017>,
			<5955 5612 5262 5077 5031 5019>,
			<5974 5633 5273 5078 5035 5023>,
			<5994 5655 5287 5079 5037 5026>,
			<6014 5680 5303 5081 5037 5027>,
			<6033 5705 5322 5082 5036 5027>,
			<6055 5734 5342 5083 5035 5025>,
			<6078 5766 5363 5084 5030 5020>,
			<6104 5800 5386 5085 5026 5017>,
			<6131 5836 5413 5088 5027 5018>,
			<6161 5875 5443 5092 5030 5022>,
			<6193 5914 5481 5097 5032 5023>,
			<6230 5954 5527 5104 5031 5023>,
			<6275 5995 5585 5112 5031 5021>,
			<6332 6038 5659 5123 5031 5016>,
			<6416 6098 5755 5145 5039 5027>,
			<6442 6114 5759 5147 5046 5035>,
			<6443 6123 5770 5154 5053 5044>,
			<6529 6182 5831 5172 5064 5054>,
			<6645 6252 5887 5193 5065 5052>,
			<6811 6330 5946 5191 5052 5033>,
			<7189 6452 6017 5198 5046 5029>,
			<8533 6729 6140 5240 5054 5034>,
			<11639 7693 6366 5305 5069 5045>,
			<11639 7693 6366 5305 5069 5045>,
			<11639 7693 6366 5305 5069 5045>;
	};

};
